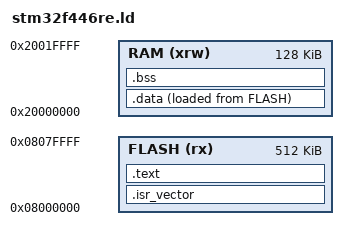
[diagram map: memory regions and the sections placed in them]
/* STM32F446RE (NUCLEO-F446RE) memory layout */
MEMORY
{
  FLASH (rx)  : ORIGIN = 0x08000000, LENGTH = 512K
  RAM   (xrw) : ORIGIN = 0x20000000, LENGTH = 128K
}

_estack = ORIGIN(RAM) + LENGTH(RAM);

SECTIONS
{
  .isr_vector :
  {
    . = ALIGN(4);
    KEEP(*(.isr_vector))
    . = ALIGN(4);
  } > FLASH

  .text :
  {
    . = ALIGN(4);
    *(.text*)
    *(.rodata*)
    *(.glue_7)
    *(.glue_7t)
    *(.eh_frame*)
    . = ALIGN(4);
  } > FLASH

  .data :
  {
    . = ALIGN(4);
    _sdata = .;
    *(.data*)
    . = ALIGN(4);
    _edata = .;
  } > RAM AT > FLASH

  _sidata = LOADADDR(.data);

  .bss :
  {
    . = ALIGN(4);
    _sbss = .;
    *(.bss*)
    *(COMMON)
    . = ALIGN(4);
    _ebss = .;
  } > RAM

  /DISCARD/ :
  {
    *(.note*)
    *(.comment*)
  }
}
